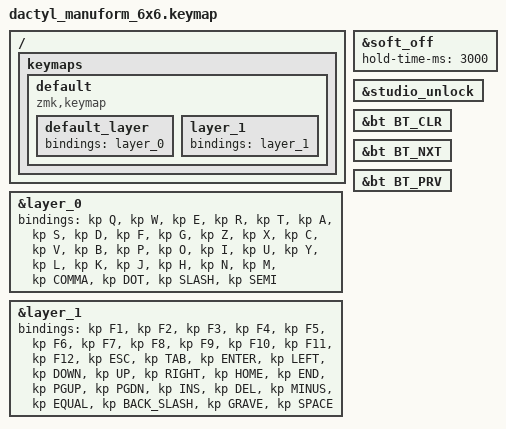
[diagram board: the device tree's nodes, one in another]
#include <behaviors.dtsi>
#include <dt-bindings/zmk/bt.h>
#include <dt-bindings/zmk/keys.h>
#include <dt-bindings/zmk/outputs.h>

&soft_off {
    hold-time-ms = <3000>;
};

&studio_unlock {
};

&bt BT_CLR {
};
&bt BT_NXT {
};
&bt BT_PRV {
};

&mo 1;
&tg 1;

&layer_0 {
    bindings = <
        &kp Q &kp W &kp E &kp R &kp T
        &kp A &kp S &kp D &kp F &kp G
        &kp Z &kp X &kp C &kp V &kp B
        &kp P &kp O &kp I &kp U &kp Y
        &kp L &kp K &kp J &kp H &kp N
        &kp M &kp COMMA &kp DOT &kp SLASH &kp SEMI
    >;
};

&layer_1 {
    bindings = <
        &kp F1 &kp F2 &kp F3 &kp F4 &kp F5
        &kp F6 &kp F7 &kp F8 &kp F9 &kp F10
        &kp F11 &kp F12 &kp ESC &kp TAB &kp ENTER
        &kp LEFT &kp DOWN &kp UP &kp RIGHT &kp HOME
        &kp END &kp PGUP &kp PGDN &kp INS &kp DEL
        &kp MINUS &kp EQUAL &kp BACK_SLASH &kp GRAVE &kp SPACE
    >;
};

/ {
    keymaps {
        default {
            compatible = "zmk,keymap";
            default_layer {
                bindings = <&layer_0>;
            };
            layer_1 {
                bindings = <&layer_1>;
            };
        };
    };
};
